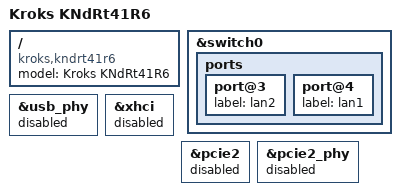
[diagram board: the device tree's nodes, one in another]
#include "mt7621_kroks_wifi_mt7603_mt7613.dtsi"

/ {
	compatible = "kroks,kndrt41r6", "mediatek,mt7621-soc";
	model = "Kroks KNdRt41R6";
};

&switch0 {
	ports {
		port@3 {
			status = "okay";
			label = "lan2";
		};

		port@4 {
			status = "okay";
			label = "lan1";
		};
	};
};

&usb_phy {
	status = "disabled";
};

&xhci {
	status = "disabled";
};

&pcie2 {
	status = "disabled";
};

&pcie2_phy {
	status = "disabled";
};
